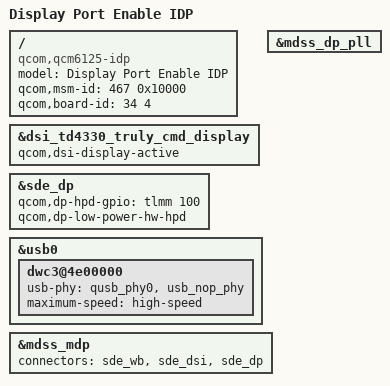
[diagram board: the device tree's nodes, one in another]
/* Copyright (c) 2020, The Linux Foundation. All rights reserved.
 *
 * This program is free software; you can redistribute it and/or modify
 * it under the terms of the GNU General Public License version 2 and
 * only version 2 as published by the Free Software Foundation.
 *
 * This program is distributed in the hope that it will be useful,
 * but WITHOUT ANY WARRANTY; without even the implied warranty of
 * MERCHANTABILITY or FITNESS FOR A PARTICULAR PURPOSE.  See the
 * GNU General Public License for more details.
 */

/dts-v1/;
/plugin/;

#include <dt-bindings/interrupt-controller/arm-gic.h>
#include <dt-bindings/clock/qcom,gcc-trinket.h>
#include "qcm6125-iot-idp.dtsi"
#include "trinket-audio-overlay.dtsi"

/ {
	model = "Display Port Enable IDP";
	compatible = "qcom,qcm6125-idp", "qcom,qcm6125", "qcom,idp";
	qcom,msm-id = <467 0x10000>;
	qcom,board-id = <34 4>;
};

&dsi_td4330_truly_cmd_display {
	qcom,dsi-display-active;
};

&sde_dp {
	status = "ok";
	qcom,dp-hpd-gpio = <&tlmm 100 0>;
	qcom,dp-low-power-hw-hpd;
};

&mdss_dp_pll {
	status = "ok";
};

&usb0 {
	dwc3@4e00000 {
		usb-phy = <&qusb_phy0>, <&usb_nop_phy>;
		maximum-speed = "high-speed";
	};
};

&mdss_mdp {
	connectors = <&sde_wb &sde_dsi &sde_dp>;
};
